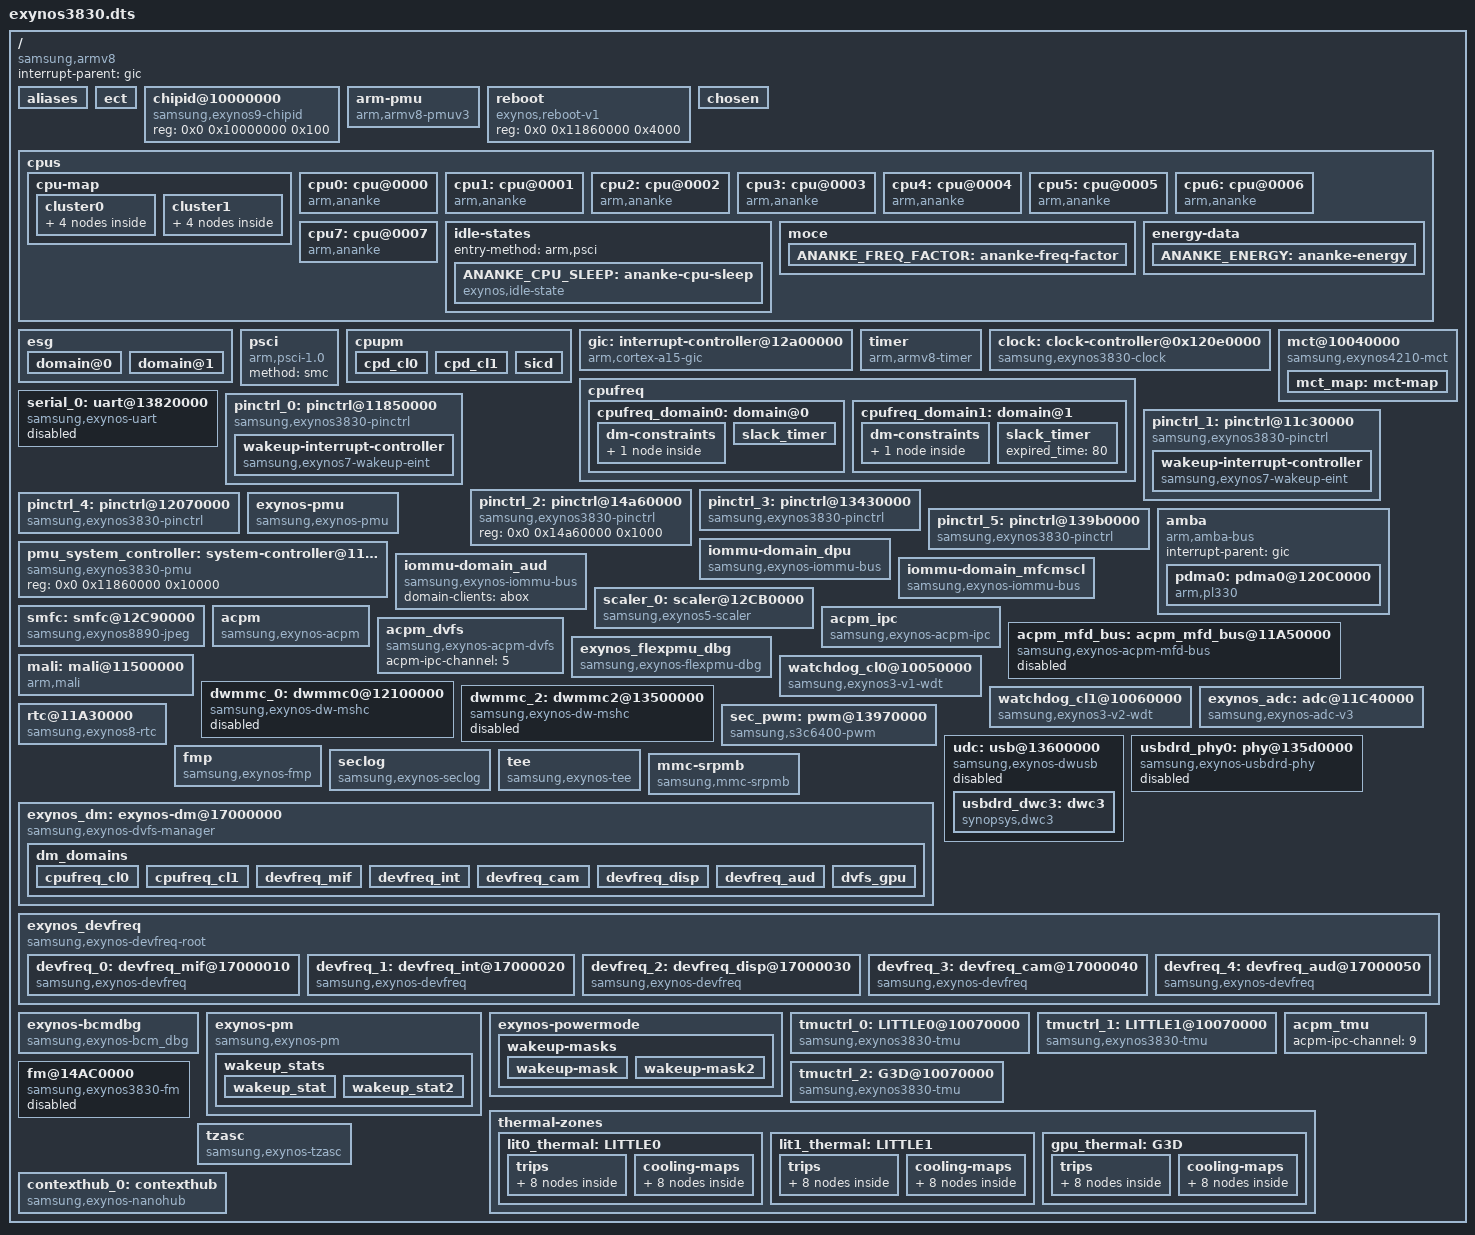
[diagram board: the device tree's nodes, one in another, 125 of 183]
/*
 * SAMSUNG EXYNOS3830 SoC device tree source
 *
 * Copyright (c) 2018 Samsung Electronics Co., Ltd.
 *		http://www.samsung.com
 *
 * SAMSUNG EXYNOS3830 SoC device nodes are listed in this file.
 * EXYNOS based board files can include this file and provide
 * values for board specfic bindings.
 *
 * This program is free software; you can redistribute it and/or modify
 * it under the terms of the GNU General Public License version 2 as
 * published by the Free Software Foundation.
 */

/dts-v1/;
#include <dt-bindings/interrupt-controller/arm-gic.h>
#include <dt-bindings/interrupt-controller/exynos3830.h>
#include <dt-bindings/clock/exynos3830.h>
#include <dt-bindings/soc/samsung/exynos3830-dm.h>
#include <dt-bindings/soc/samsung/exynos3830-devfreq.h>
#include <dt-bindings/soc/samsung/exynos-bcm_dbg.h>
#include "exynos3830-pinctrl.dtsi"
#include "exynos3830-rmem.dtsi"
#include "exynos3830-sysmmu.dtsi"
#include "exynos3830-dpu.dtsi"
#include "exynos3830-usi.dtsi"
#include "exynos3830-debug.dtsi"
#include "exynos-dpm.dtsi"
#include "exynos3830-pm-domains.dtsi"
#include "exynos3830-bts.dtsi"
#include "exynos3830-mfc.dtsi"
#include "exynos3830-camera.dtsi"
#include <dt-bindings/soc/samsung/exynos-ecs.h>
#include "exynos3830-wlbt.dtsi"
#include "exynos3830-ems.dtsi"
#include "exynos3830-audio.dtsi"
#include "exynos_perf_ncmemcpy.dtsi"

/ {
	compatible = "samsung,armv8", "samsung,exynos3830";
	interrupt-parent = <&gic>;
	#address-cells = <2>;
	#size-cells = <1>;

	aliases {
		pinctrl0 = &pinctrl_0;
		pinctrl1 = &pinctrl_1;
		pinctrl2 = &pinctrl_2;
		pinctrl3 = &pinctrl_3;
		pinctrl4 = &pinctrl_4;
		pinctrl5 = &pinctrl_5;
		uart0 = &serial_0;
		mshc0 = &dwmmc_0;
		mshc2 = &dwmmc_2;
		mfc0 = &mfc_0;
		scaler0 = &scaler_0;
		contexthub0 = &contexthub_0;
	};

	ect {
		parameter_address = <0x90000000>;
		parameter_size = <0x4B000>;
	};

	chipid@10000000 {
		compatible = "samsung,exynos9-chipid";
		reg = <0x0 0x10000000 0x100>;
	};

	arm-pmu {
		compatible = "arm,armv8-pmuv3";
		interrupts =	<0 INTREQ__CPUCL0_PMUIRQ_0 IRQ_TYPE_LEVEL_HIGH>,
				<0 INTREQ__CPUCL0_PMUIRQ_1 IRQ_TYPE_LEVEL_HIGH>,
				<0 INTREQ__CPUCL0_PMUIRQ_2 IRQ_TYPE_LEVEL_HIGH>,
				<0 INTREQ__CPUCL0_PMUIRQ_3 IRQ_TYPE_LEVEL_HIGH>,
				<0 INTREQ__CPUCL1_PMUIRQ_0 IRQ_TYPE_LEVEL_HIGH>,
				<0 INTREQ__CPUCL1_PMUIRQ_1 IRQ_TYPE_LEVEL_HIGH>,
				<0 INTREQ__CPUCL1_PMUIRQ_2 IRQ_TYPE_LEVEL_HIGH>,
				<0 INTREQ__CPUCL1_PMUIRQ_3 IRQ_TYPE_LEVEL_HIGH>;
		interrupt-affinity =	<&cpu0>,
					<&cpu1>,
					<&cpu2>,
					<&cpu3>,
					<&cpu4>,
					<&cpu5>,
					<&cpu6>,
					<&cpu7>;
	};

	reboot {
		compatible = "exynos,reboot-v1";
		reg = <0x0 0x11860000 0x4000>;
	};

	chosen: chosen {
		bootargs = "console=ttySAC0,115200n8 clk_ignore_unused root=/dev/ram0 androidboot.boot_devices=12100000.dwmmc0 androidboot.dtbo_idx=0 androidboot.debug_level=0x4948 firmware_class.path=/vendor/firmware pmic_info=0x3 ccic_info=0x0 reserve-fimc=0xffffff90f9fe0000";
		linux,initrd-start = <0x84000000>;
		linux,initrd-end = <0x841FFFFF>;
	};

	cpus {
		#address-cells = <2>;
		#size-cells = <0>;

		cpu-map {
			cluster0 {
				core0 {
					cpu = <&cpu0>;
				};
				core1 {
					cpu = <&cpu1>;
				};
				core2 {
					cpu = <&cpu2>;
				};
				core3 {
					cpu = <&cpu3>;
				};
			};

			cluster1 {
				core0 {
					cpu = <&cpu4>;
				};
				core1 {
					cpu = <&cpu5>;
				};
				core2 {
					cpu = <&cpu6>;
				};
				core3 {
					cpu = <&cpu7>;
				};
			};
		};

		cpu0: cpu@0000 {
			device_type = "cpu";
			compatible = "arm,ananke", "arm,armv8";
			reg = <0x0 0x0000>;
			enable-method = "psci";
			sched-energy-data = <&ANANKE_ENERGY>;
			cpu-idle-states = <&ANANKE_CPU_SLEEP>;
			moce-factors = <&ANANKE_FREQ_FACTOR>;
		};
		cpu1: cpu@0001 {
			device_type = "cpu";
			compatible = "arm,ananke", "arm,armv8";
			reg = <0x0 0x0001>;
			enable-method = "psci";
			sched-energy-data = <&ANANKE_ENERGY>;
			cpu-idle-states = <&ANANKE_CPU_SLEEP>;
			moce-factors = <&ANANKE_FREQ_FACTOR>;
		};
		cpu2: cpu@0002 {
			device_type = "cpu";
			compatible = "arm,ananke", "arm,armv8";
			reg = <0x0 0x0002>;
			enable-method = "psci";
			sched-energy-data = <&ANANKE_ENERGY>;
			cpu-idle-states = <&ANANKE_CPU_SLEEP>;
			moce-factors = <&ANANKE_FREQ_FACTOR>;
		};
		cpu3: cpu@0003 {
			device_type = "cpu";
			compatible = "arm,ananke", "arm,armv8";
			reg = <0x0 0x0003>;
			enable-method = "psci";
			sched-energy-data = <&ANANKE_ENERGY>;
			cpu-idle-states = <&ANANKE_CPU_SLEEP>;
			moce-factors = <&ANANKE_FREQ_FACTOR>;
		};
		cpu4: cpu@0004 {
			device_type = "cpu";
			compatible = "arm,ananke", "arm,armv8";
			reg = <0x0 0x0100>;
			enable-method = "psci";
			sched-energy-data = <&ANANKE_ENERGY>;
			cpu-idle-states = <&ANANKE_CPU_SLEEP>;
			moce-factors = <&ANANKE_FREQ_FACTOR>;
		};
		cpu5: cpu@0005 {
			device_type = "cpu";
			compatible = "arm,ananke", "arm,armv8";
			reg = <0x0 0x0101>;
			enable-method = "psci";
			sched-energy-data = <&ANANKE_ENERGY>;
			cpu-idle-states = <&ANANKE_CPU_SLEEP>;
			moce-factors = <&ANANKE_FREQ_FACTOR>;
		};
		cpu6: cpu@0006 {
			device_type = "cpu";
			compatible = "arm,ananke", "arm,armv8";
			reg = <0x0 0x0102>;
			enable-method = "psci";
			sched-energy-data = <&ANANKE_ENERGY>;
			cpu-idle-states = <&ANANKE_CPU_SLEEP>;
			moce-factors = <&ANANKE_FREQ_FACTOR>;
		};
		cpu7: cpu@0007 {
			device_type = "cpu";
			compatible = "arm,ananke", "arm,armv8";
			reg = <0x0 0x0103>;
			enable-method = "psci";
			sched-energy-data = <&ANANKE_ENERGY>;
			cpu-idle-states = <&ANANKE_CPU_SLEEP>;
			moce-factors = <&ANANKE_FREQ_FACTOR>;
		};

		idle-states {
			entry-method = "arm,psci";

			ANANKE_CPU_SLEEP: ananke-cpu-sleep {
				idle-state-name = "c2";
				compatible = "exynos,idle-state";
				arm,psci-suspend-param = <0x0010000>;
				entry-latency-us = <70>;
				exit-latency-us = <160>;
				min-residency-us = <2000>;
				status = "okay";
			};
		};

		moce {
			#define FREQ_FACTOR     0

			/* factor table format: [ratio][factor][ratio]...[ratio] */
			ANANKE_FREQ_FACTOR: ananke-freq-factor {
				sibling-cpus = "0-7";
				type = <FREQ_FACTOR>;
				ratio-table = <100>;
			};
		};

		energy-data {
			ANANKE_ENERGY: ananke-energy {
				mips-per-mhz = <271>;
				power-coefficient = <125>;
				mips-per-mhz-s = <215>;
				power-coefficient-s = <110>;
				static-power-coefficient = <10>;

				efficiency-weight = <100>;
				efficiency-weight-perf = <200>;
			};
		};
	};

	esg {
		domain@0 {
			device_type = "esgov-pol0";
			shared-cpus = "0-3";
			pm_qos-min-class = <3>;
			pm_qos-max-class = <4>;
			step = <4>;
		};
		domain@1 {
			device_type = "esgov-pol4";
			shared-cpus = "4-7";
			pm_qos-min-class = <5>;
			pm_qos-max-class = <6>;
			step = <4>;
		};
	};

	psci {
		compatible = "arm,psci-1.0";
		method = "smc";
	};

	cpupm {
		#define POWERMODE_TYPE_CLUSTER  0
		#define POWERMODE_TYPE_SYSTEM   1

		cpd_cl0 {
			device_type = "cpupm";
			target-residency = <10000>;
			psci-index = <128>;
			type = <POWERMODE_TYPE_CLUSTER>;
			siblings = "0-3";
		};

		cpd_cl1 {
			device_type = "cpupm";
			target-residency = <10000>;
			psci-index = <128>;
			type = <POWERMODE_TYPE_CLUSTER>;
			siblings = "4-7";
		};

               sicd {
                       device_type = "cpupm";
                       target-residency = <10000>;
                       psci-index = <256>;
                       type = <POWERMODE_TYPE_SYSTEM>;
                       siblings = "0-7";
		       entry-allowed = "0-7";
                       system-idle;
               };
	};

	gic:interrupt-controller@12a00000 {
		compatible = "arm,cortex-a15-gic", "arm,cortex-a9-gic";
		#interrupt-cells = <3>;
		#address-cells = <0>;
		interrupt-controller;
		reg =	<0x0 0x12a01000 0x1000>,
			<0x0 0x12a02000 0x1000>,
			<0x0 0x12a04000 0x2000>,
			<0x0 0x12a06000 0x2000>;
		interrupts = <1 9 0xf04>;
	};

	timer {
	        compatible = "arm,armv8-timer";
		interrupts = <GIC_PPI 13
				(GIC_CPU_MASK_SIMPLE(8) | IRQ_TYPE_LEVEL_LOW)>,
			     <GIC_PPI 14
				(GIC_CPU_MASK_SIMPLE(8) | IRQ_TYPE_LEVEL_LOW)>,
			     <GIC_PPI 11
				(GIC_CPU_MASK_SIMPLE(8) | IRQ_TYPE_LEVEL_LOW)>,
			     <GIC_PPI 10
				(GIC_CPU_MASK_SIMPLE(8) | IRQ_TYPE_LEVEL_LOW)>;
	        clock-frequency = <26000000>;
		use-clocksource-only;
		use-physical-timer;
	};

	clock: clock-controller@0x120e0000 {
		compatible = "samsung,exynos3830-clock";
		reg = <0x0 0x120e0000 0x8000>;
		#clock-cells = <1>;
		acpm-ipc-channel = <0>;
	};

	cpufreq {
		cpufreq_domain0: domain@0 {
			device_type = "cpufreq-domain";
			sibling-cpus = "0-3";
			cal-id = <ACPM_DVFS_CPUCL0>;
			dm-type = <DM_CPU_CL0>;

			min-freq = <546000>;

			/* PM QoS Class ID*/
			pm_qos-min-class = <3>;
			pm_qos-max-class = <4>;

			#cooling-cells = <2>; /* min followed by max */

			dm-constraints {
				mif-perf {
					const-type = <CONSTRAINT_MIN>;
					dm-type = <DM_MIF>;
					/*  cpu     mif  */
					table = < 2002000  1539000
						  1846000  1539000
						  1742000  1352000
						  1586000  1352000
						  1456000  1014000
						  1300000  1014000
						  1157000   845000
						  1053000   845000
						   949000   676000
						   806000   676000
						   650000   676000
						   546000   676000
						   442000   676000
						>;
				};
			};

			slack_timer {
				device_type = "slack-timer-domain";
			};
		};

		cpufreq_domain1: domain@1 {
			device_type = "cpufreq-domain";
			sibling-cpus = "4-7";
			cal-id = <ACPM_DVFS_CPUCL1>;
			dm-type = <DM_CPU_CL1>;

			min-freq = <546000>;

			/* PM QoS Class ID*/
			pm_qos-min-class = <5>;
			pm_qos-max-class = <6>;

			#cooling-cells = <2>; /* min followed by max */

			dm-constraints {
				mif-perf {
					const-type = <CONSTRAINT_MIN>;
					dm-type = <DM_MIF>;
					/*  cpu     mif  */
					table = < 2002000  1539000
						  1846000  1539000
						  1742000  1352000
						  1586000  1352000
						  1456000  1014000
						  1300000  1014000
						  1157000   845000
						  1053000   845000
						   949000   676000
						   806000   676000
						   650000   676000
						   546000   676000
						   442000   676000
						>;
				};
			};

			slack_timer {
				device_type = "slack-timer-domain";
				expired_time = <80>;	/* 80ms */
			};
		};
	};

	mct@10040000 {
		compatible = "samsung,exynos4210-mct";
		reg = <0x0 0x10040000 0x800>;
		interrupt-controller;
		#interrupt-cells = <1>;
		interrupt-parent = <&mct_map>;
		interrupts =	<0>, <1>, <2>, <3>,
				<4>, <5>, <6>, <7>,
				<8>, <9>, <10>, <11>;
		clocks = <&clock OSCCLK>, <&clock GATE_MCT_QCH>;
		clock-names = "fin_pll", "mct";
		use-clockevent-only;

		mct_map: mct-map {
			#interrupt-cells = <1>;
			#address-cells = <0>;
			#size-cells = <0>;
			interrupt-map = <0 &gic 0 INTREQ__MCT_G0 IRQ_TYPE_LEVEL_HIGH>,
					<1 &gic 0 INTREQ__MCT_G1 IRQ_TYPE_LEVEL_HIGH>,
					<2 &gic 0 INTREQ__MCT_G2 IRQ_TYPE_LEVEL_HIGH>,
					<3 &gic 0 INTREQ__MCT_G3 IRQ_TYPE_LEVEL_HIGH>,
					<4 &gic 0 INTREQ__MCT_L0 IRQ_TYPE_LEVEL_HIGH>,
					<5 &gic 0 INTREQ__MCT_L1 IRQ_TYPE_LEVEL_HIGH>,
					<6 &gic 0 INTREQ__MCT_L2 IRQ_TYPE_LEVEL_HIGH>,
					<7 &gic 0 INTREQ__MCT_L3 IRQ_TYPE_LEVEL_HIGH>,
					<8 &gic 0 INTREQ__MCT_L4 IRQ_TYPE_LEVEL_HIGH>,
					<9 &gic 0 INTREQ__MCT_L5 IRQ_TYPE_LEVEL_HIGH>,
					<10 &gic 0 INTREQ__MCT_L6 IRQ_TYPE_LEVEL_HIGH>,
					<11 &gic 0 INTREQ__MCT_L7 IRQ_TYPE_LEVEL_HIGH>;
		};
	};

	serial_0: uart@13820000 {
		compatible = "samsung,exynos-uart";
		samsung,separate-uart-clk;
		reg = <0x0 0x13820000 0x100>;
		samsung,fifo-size = <64>;
		interrupts = <0 INTREQ__UART 0>;
		pinctrl-names = "default","sleep";
		pinctrl-0 = <&uart0_bus>;
		pinctrl-1 = <&uart0_bus_sleep>;
		samsung,usi-serial-v2;
		samsung,dbg-uart-ch;
		samsung,dbg-uart-baud = <115200>;
		samsung,dbg-word-len = <8>;
		clocks = <&clock GATE_UART_QCH>, <&clock DOUT_UART>;
		clock-names = "gate_uart_clk0", "ipclk_uart0";
		status = "disabled";
	};

	/* ALIVE */
	pinctrl_0: pinctrl@11850000 {
		compatible = "samsung,exynos3830-pinctrl";
		reg = <0x0 0x11850000 0x1000>;
		interrupts = <GIC_SPI INTREQ__ALIVE_EINT0 IRQ_TYPE_LEVEL_HIGH>,
			     <GIC_SPI INTREQ__ALIVE_EINT1 IRQ_TYPE_LEVEL_HIGH>,
			     <GIC_SPI INTREQ__ALIVE_EINT2 IRQ_TYPE_LEVEL_HIGH>,
			     <GIC_SPI INTREQ__ALIVE_EINT3 IRQ_TYPE_LEVEL_HIGH>,
			     <GIC_SPI INTREQ__ALIVE_EINT4 IRQ_TYPE_LEVEL_HIGH>,
			     <GIC_SPI INTREQ__ALIVE_EINT5 IRQ_TYPE_LEVEL_HIGH>,
			     <GIC_SPI INTREQ__ALIVE_EINT6 IRQ_TYPE_LEVEL_HIGH>,
			     <GIC_SPI INTREQ__ALIVE_EINT7 IRQ_TYPE_LEVEL_HIGH>,
			     <GIC_SPI INTREQ__ALIVE_EINT8 IRQ_TYPE_LEVEL_HIGH>,
			     <GIC_SPI INTREQ__ALIVE_EINT9 IRQ_TYPE_LEVEL_HIGH>,
			     <GIC_SPI INTREQ__ALIVE_EINT10 IRQ_TYPE_LEVEL_HIGH>,
			     <GIC_SPI INTREQ__ALIVE_EINT11 IRQ_TYPE_LEVEL_HIGH>,
			     <GIC_SPI INTREQ__ALIVE_EINT12 IRQ_TYPE_LEVEL_HIGH>,
			     <GIC_SPI INTREQ__ALIVE_EINT13 IRQ_TYPE_LEVEL_HIGH>,
			     <GIC_SPI INTREQ__ALIVE_EINT14 IRQ_TYPE_LEVEL_HIGH>,
			     <GIC_SPI INTREQ__ALIVE_EINT15 IRQ_TYPE_LEVEL_HIGH>,
			     <GIC_SPI INTREQ__ALIVE_EINT16 IRQ_TYPE_LEVEL_HIGH>,
			     <GIC_SPI INTREQ__ALIVE_EINT17 IRQ_TYPE_LEVEL_HIGH>,
			     <GIC_SPI INTREQ__ALIVE_EINT18 IRQ_TYPE_LEVEL_HIGH>,
			     <GIC_SPI INTREQ__ALIVE_EINT19 IRQ_TYPE_LEVEL_HIGH>,
			     <GIC_SPI INTREQ__ALIVE_EINT20 IRQ_TYPE_LEVEL_HIGH>,
			     <GIC_SPI INTREQ__ALIVE_EINT21 IRQ_TYPE_LEVEL_HIGH>,
			     <GIC_SPI INTREQ__ALIVE_EINT22 IRQ_TYPE_LEVEL_HIGH>,
			     <GIC_SPI INTREQ__ALIVE_EINT23 IRQ_TYPE_LEVEL_HIGH>,
			     <GIC_SPI INTREQ__ALIVE_EINT24 IRQ_TYPE_LEVEL_HIGH>,
			     <GIC_SPI INTREQ__ALIVE_EINT25 IRQ_TYPE_LEVEL_HIGH>,
			     <GIC_SPI INTREQ__ALIVE_EINT26 IRQ_TYPE_LEVEL_HIGH>,
			     <GIC_SPI INTREQ__ALIVE_EINT27 IRQ_TYPE_LEVEL_HIGH>,
			     <GIC_SPI INTREQ__ALIVE_EINT28 IRQ_TYPE_LEVEL_HIGH>,
			     <GIC_SPI INTREQ__ALIVE_EINT29 IRQ_TYPE_LEVEL_HIGH>,
			     <GIC_SPI INTREQ__ALIVE_EINT30 IRQ_TYPE_LEVEL_HIGH>,
			     <GIC_SPI INTREQ__ALIVE_EINT31 IRQ_TYPE_LEVEL_HIGH>;

		wakeup-interrupt-controller {
			compatible = "samsung,exynos7-wakeup-eint";
		};
	};

	/* CMGP */
	pinctrl_1: pinctrl@11c30000 {
		compatible = "samsung,exynos3830-pinctrl";
		reg = <0x0 0x11c30000 0x1000>;
		interrupts = <GIC_SPI INTREQ__CMGP_EXT_INTM00 IRQ_TYPE_LEVEL_HIGH>,
			     <GIC_SPI INTREQ__CMGP_EXT_INTM01 IRQ_TYPE_LEVEL_HIGH>,
			     <GIC_SPI INTREQ__CMGP_EXT_INTM02 IRQ_TYPE_LEVEL_HIGH>,
			     <GIC_SPI INTREQ__CMGP_EXT_INTM03 IRQ_TYPE_LEVEL_HIGH>,
			     <GIC_SPI INTREQ__CMGP_EXT_INTM04 IRQ_TYPE_LEVEL_HIGH>,
			     <GIC_SPI INTREQ__CMGP_EXT_INTM05 IRQ_TYPE_LEVEL_HIGH>,
			     <GIC_SPI INTREQ__CMGP_EXT_INTM06 IRQ_TYPE_LEVEL_HIGH>,
			     <GIC_SPI INTREQ__CMGP_EXT_INTM07 IRQ_TYPE_LEVEL_HIGH>;

		wakeup-interrupt-controller {
			compatible = "samsung,exynos7-wakeup-eint";
		};
	};

	/* AUD */
	pinctrl_2: pinctrl@14a60000 {
		compatible = "samsung,exynos3830-pinctrl";
		reg = <0x0 0x14a60000 0x1000>;
	};

	/* HSI */
	pinctrl_3: pinctrl@13430000 {
		compatible = "samsung,exynos3830-pinctrl";
		reg = <0x0 0x13430000 0x1000>;
		interrupts = <GIC_SPI INTREQ__GPIO_HSI IRQ_TYPE_LEVEL_HIGH>;
	};

	/* CORE */
	pinctrl_4: pinctrl@12070000 {
		compatible = "samsung,exynos3830-pinctrl";
		reg = <0x0 0x12070000 0x1000>;
		interrupts = <GIC_SPI INTREQ__GPIO_CORE IRQ_TYPE_LEVEL_HIGH>;
	};

	/* PERI */
	pinctrl_5: pinctrl@139b0000 {
		compatible = "samsung,exynos3830-pinctrl";
		reg = <0x0 0x139b0000 0x1000>;
		interrupts = <GIC_SPI INTREQ__GPIO_PERI IRQ_TYPE_LEVEL_HIGH>;
	};

	exynos-pmu {
		compatible = "samsung,exynos-pmu";
		samsung,syscon-phandle = <&pmu_system_controller>;
		reg = <0x0 0x11860000 0x10000>;
		reg-names = "pmu_alive";
	};

	pmu_system_controller: system-controller@11860000 {
		compatible = "samsung,exynos3830-pmu", "syscon";
		reg = <0x0 0x11860000 0x10000>;
	};

	/* DMA */
	amba {
		#address-cells = <2>;
		#size-cells = <1>;
		compatible = "arm,amba-bus";
		interrupt-parent = <&gic>;
		ranges;

		pdma0: pdma0@120C0000 {
			compatible = "arm,pl330", "arm,primecell";
			reg = <0x0 0x120C0000 0x1000>;
			interrupts = <0 479 0>;
			clocks = <&clock GATE_PDMA_CORE_QCH>;
			clock-names = "apb_pclk";
			#dma-cells = <1>;
			#dma-channels = <8>;
			#dma-requests = <32>;
			#dma-multi-irq = <1>;
			dma-arwrapper = <0x120C4400>,
					<0x120C4420>,
					<0x120C4440>,
					<0x120C4460>,
					<0x120C4480>,
					<0x120C44A0>,
					<0x120C44C0>,
					<0x120C44E0>;
			dma-awwrapper = <0x120C4404>,
					<0x120C4424>,
					<0x120C4444>,
					<0x120C4464>,
					<0x120C4484>,
					<0x120C44A4>,
					<0x120C44C4>,
					<0x120C44E4>;
			dma-instwrapper = <0x120C4500>;
			dma-mask-bit = <36>;
			coherent-mask-bit = <36>;
		};
	};

	iommu-domain_dpu {
		compatible = "samsung,exynos-iommu-bus";
		#dma-address-cells = <1>;
		#dma-size-cells = <1>;
		ranges;
		/* start address, size */
		dma-window = <0x10000000 0xEFFF0000>;

		domain-clients = <&dsim_0>;
	};

	iommu-domain_aud {
		compatible = "samsung,exynos-iommu-bus";
		#address-cells = <2>;
		#size-cells = <1>;
		ranges;

		domain-clients = <&abox>;
	};

	iommu-domain_mfcmscl {
		compatible = "samsung,exynos-iommu-bus";
		#address-cells = <2>;
		#size-cells = <1>;
		ranges;

		domain-clients = <&mfc_0>, <&scaler_0>, <&smfc>,
					<&exynos_is>, <&is_sensor0>, <&is_sensor1>,
					<&is_sensor2>, <&camerapp_gdc>;
	};

	scaler_0: scaler@12CB0000 {
		compatible = "samsung,exynos5-scaler";
		reg = <0x0 0x12CB0000 0x3000>;
		interrupts = <0 170 0>;
		clocks = <&clock GATE_M2M_QCH>;
		clock-names = "gate";
		iommus = <&sysmmu_mfcmscl>;

		/* MIF | INT | datasize (not used) */
		mscl_qos_table = < 1352000 534000 0
				   1014000 334000 0
				    676000 200000 0
				    421000 100000 0 >;
		/* bpp means, YUV420(12), YUV422(16), RGB(32) */
		/* bpp | ppc * 100 | ppc * 100 with rotation */
		mscl_ppc_table = <  12  79 79
				    16  66 66
				    32  82 79 >;
	};

	smfc: smfc@12C90000 {
		compatible = "samsung,exynos8890-jpeg";
		reg = <0x0 0x12C90000 0x1000>;
		interrupts = <0 INTREQ__JPEG 0>;
		clocks = <&clock GATE_JPEG_QCH>;
		clock-names = "gate";
		iommus = <&sysmmu_mfcmscl>;
		smfc,int_qos_minlock = <534000>;
	};

	acpm {
		compatible = "samsung,exynos-acpm";
		#address-cells = <2>;
		#size-cells = <1>;
		acpm-ipc-channel = <4>;
		fvmap_offset = <0xA000>;
		reg = <0x0 0x11830000 0x1000>;		/* TIMER_APM */
		reg-names = "timer_apm";
		peritimer-cnt = <0xFFFF>;
	};

	acpm_ipc {
		compatible = "samsung,exynos-acpm-ipc";
		#address-cells = <2>;
		#size-cells = <1>;
		interrupts = <0 INTREQ__MAILBOX_APM2AP 0>;	/* AP2APM MAILBOX SPI NUM*/
		reg = <0x0 0x11900000 0x1000>,		/* AP2APM MAILBOX */
			<0x0 0x2039000 0x30000>;	/* APM SRAM */
		initdata-base = <0x7000>;
		num-timestamps = <32>;
		debug-log-level = <0>;
		logging-period = <500>;
		dump-base = <0x203C000>;
		dump-size = <0x2D000>;			/* 180KB */
	};

	acpm_dvfs {
		compatible = "samsung,exynos-acpm-dvfs";
		acpm-ipc-channel = <5>;
	};

	acpm_mfd_bus: acpm_mfd_bus@11A50000 {
		compatible = "samsung,exynos-acpm-mfd-bus";
		status = "disabled";
	};

	exynos_flexpmu_dbg {
		compatible = "samsung,exynos-flexpmu-dbg";
		#address-cells = <2>;
		#size-cells = <1>;
		data-base = <0x204D400>;
		data-size = <0x400>;
		reg = <0x0 0x11a30000 0x1000>;
	};

    /* mali */
    mali: mali@11500000 {
        compatible = "arm,mali";
        reg = <0x0 0x11500000 0x5000>;
        interrupts = <GIC_SPI INTREQ__G3D_IRQJOB IRQ_TYPE_LEVEL_HIGH>,
                   <GIC_SPI INTREQ__G3D_IRQMMU IRQ_TYPE_LEVEL_HIGH>,
                   <GIC_SPI INTREQ__G3D_IRQGPU IRQ_TYPE_LEVEL_HIGH>;
        interrupt-names = "JOB", "MMU", "GPU";
        g3d_cmu_cal_id = <ACPM_DVFS_G3D>;
        samsung,power-domain = <&pd_g3d>;
        g3d_genpd_name = "pd-g3d";
        #cooling-cells = <2>; /* min followed by max */
        governor = "interactive";
        interactive_info = <377000 75 0>;
        gpu_dvfs_table_size = <6 7>; /*<row col>*/
        /*  8 columns          freq  down   up stay     mif  little     big  */
        gpu_dvfs_table = <  1001000    95  100   1  1539000 2002000       0
                             865000    80   90   1  1539000 2002000       0
                             754000    80   90   1  1352000 1456000       0
                             598000    70   90   1  1014000 1053000       0
                             433000    60   80   1   845000  806000       0
                             377000     0   70   1   676000  650000       0  >;
        gpu_sustainable_info = <0 0 0 0 0>;
        gpu_pmqos_cpu_cluster_num = <2>;
        gpu_pmu_status_reg_offset = <0x1d04>;
        gpu_pmu_status_local_pwr_mask = <0x1>; /*0x1 << 0*/
        gpu_max_clock = <1001000>;
        gpu_max_clock_limit = <1001000>;
        gpu_min_clock = <377000>;
        gpu_dvfs_start_clock = <377000>;
        gpu_dvfs_bl_config_clock = <377000>;
        gpu_default_voltage = <800000>;
        gpu_cold_minimum_vol = <0>;
        gpu_voltage_offset_margin = <37500>;
        gpu_tmu_control = <1>;
        gpu_temp_throttling_level_num = <6>;
        gpu_temp_throttling = <598000 433000 377000 156000 100000 100000>;
        gpu_power_coeff = <625>;
        gpu_dvfs_time_interval = <5>; /*1 tick : 10ms*/
        gpu_default_wakeup_lock = <1>;
        gpu_dynamic_abb = <0>;
        gpu_early_clk_gating = <0>;
        gpu_dvs = <0>;
        gpu_inter_frame_pm = <0>;
        gpu_perf_gathering = <0>;
        gpu_runtime_pm_delay_time = <50>;
        gpu_dvfs_polling_time = <30>;
        gpu_pmqos_int_disable = <1>;
        gpu_pmqos_mif_max_clock = <2094000>;
        gpu_pmqos_mif_max_clock_base = <650000>;
        gpu_cl_dvfs_start_base = <377000>;
        gpu_debug_level = <3>; /*DEBUG(1) INFO(2) WARNING(3) ERROR(4)*/
        gpu_trace_level = <8>; /*TRACE_ALL*/
        gpu_mo_min_clock = <377000>;
        gpu_boost_gpu_min_lock = <0>;
        gpu_boost_egl_min_lock = <1872000>;
        gpu_vk_boost_max_lock = <325000>;
        gpu_vk_boost_mif_min_lock = <1014000>;
        gpu_bts_support = <1>;
    };

	dwmmc_0: dwmmc0@12100000 {
		compatible = "samsung,exynos-dw-mshc";
		reg = <0x0 0x12100000 0x2000>,
		    <0x0 0x12108000 0x200>;
		reg-names = "dw_mmc",
			"cmdq_mem";
		interrupts = <0 INTREQ__MMC_EMBD_CORE 0>;
		#address-cells = <1>;
		#size-cells = <0>;
		clocks = <&clock DOUT_CORE_MMC_EMBD>;
		clock-names = "ciu";
		status = "disabled";
		fmp-id = <0>;
		smu-id = <0>;
	 };

	dwmmc_2: dwmmc2@13500000 {
		compatible = "samsung,exynos-dw-mshc";
		reg = <0x0 0x13500000 0x2000>;
		reg-names = "dw_mmc";
		interrupts = <0 INTREQ__MMC_CARD 0>;
		#address-cells = <1>;
		#size-cells = <0>;
		clocks = <&clock HSI_MMC_CARD>;
		clock-names = "ciu";
		samsung,power-domain = <&pd_hsi>;
		status = "disabled";
	 };

	watchdog_cl0@10050000 {
		compatible = "samsung,exynos3-v1-wdt";
		reg = <0x0 0x10050000 0x100>;
		interrupts = <GIC_SPI INTREQ__WDT_0 IRQ_TYPE_LEVEL_HIGH>;
		clocks = <&clock OSCCLK>, <&clock GATE_WDT_0_QCH>;
		clock-names = "rate_watchdog", "gate_watchdog";
		timeout-sec = <30>;
		samsung,syscon-phandle = <&pmu_system_controller>;
		index = <0>; /* if little cluster then index is 0*/
	};

	watchdog_cl1@10060000 {
		compatible = "samsung,exynos3-v2-wdt";
		reg = <0x0 0x10060000 0x100>;
		interrupts = <GIC_SPI INTREQ__WDT_1 IRQ_TYPE_LEVEL_HIGH>;
		clocks = <&clock OSCCLK>, <&clock GATE_WDT_1_QCH>;
		clock-names = "rate_watchdog", "gate_watchdog";
		timeout-sec = <30>;
		samsung,syscon-phandle = <&pmu_system_controller>;
		index = <1>; /* if little cluster then index is 0*/
		use_multistage_wdt; /* Use FIQ debug watchdog */
	};

	exynos_adc: adc@11C40000 {
		compatible = "samsung,exynos-adc-v3";
		reg = <0x0 0x11C40000 0x100>;
		interrupts = <GIC_SPI INTREQ__ADC_CMGP2AP IRQ_TYPE_LEVEL_HIGH>;
		#io-channel-cells = <1>;
		io-channel-ranges;
		clocks = <&clock GATE_ADC_CMGP_QCH_S0>;
		clock-names = "gate_adcif";
	};

	sec_pwm: pwm@13970000 {
		compatible = "samsung,s3c6400-pwm";
		reg = <0x0 0x13970000 0x1000>;
		samsung,pwm-outputs = <0>, <1>, <2>, <3>, <4>;
		#pwm-cells = <3>;
		clocks = <&clock GATE_PWM_MOTOR_QCH>, <&clock OSCCLK>;
		clock-names = "pwm_pclk", "pwm_sclk";
		pinctrl-names = "default";
#if 0 //dw.choi
		pinctrl-0 = <&motor_pwm_tout0>;
#endif
		status = "ok";
	};

	rtc@11A30000 {
		compatible = "samsung,exynos8-rtc";
		reg = <0x0 0x11A30000 0x100>;
		interrupts = <GIC_SPI INTREQ__RTC_ALARM_INT IRQ_TYPE_LEVEL_HIGH>,
			     <GIC_SPI INTREQ__RTC_TIC_INT_0 IRQ_TYPE_LEVEL_HIGH>;
	};

	udc: usb@13600000 {
		compatible = "samsung,exynos-dwusb";
		pinctrl-names = "default";
		pinctrl-0 = <&fm_lna_en>;
		clocks = <&clock GATE_USB20DRD_TOP_QCH_LINK>, <&clock HSI_USB20DRD>;
		clock-names = "aclk", "sclk";
		reg = <0x0 0x13600000 0x10000>;
		#address-cells = <2>;
		#size-cells = <1>;
		ranges;
		samsung,power-domain = <&pd_hsi>;
		status = "disabled";

		usbdrd_dwc3: dwc3 {
			compatible = "synopsys,dwc3";
			reg = <0x0 0x13600000 0x10000>;
			interrupts = <0 INTREQ__USB20DRD_0 0>;
			tx-fifo-resize = <0>;
			adj-sof-accuracy = <0>;
			is_not_vbus_pad = <1>;
			enable_sprs_transfer = <1>;
			phys = <&usbdrd_phy0 0>, <&usbdrd_phy0 1>;
			phy-names = "usb2-phy", "usb3-phy";
			/* check susphy support */
			xhci_l2_support = <0>;
			/* support usb audio offloading: 1, if not: 0 */
			usb_audio_offloading = <0>;
			//abox = <&abox>; /* Temporary block */
			/* support USB L2 sleep */
			ldos = <3>;
			ldo_number = <1 2 11>;
		};
	};

	usbdrd_phy0: phy@135d0000 {
		compatible = "samsung,exynos-usbdrd-phy";
		reg = <0x0 0x135d0000 0x200>;
		interrupts = <0 INTREQ__USB2_REMOTE_WAKEUP 0>,
			     <0 INTREQ__USB2_REMOTE_CONNECT 0>;
		clocks = <&clock OSCCLK>, <&clock GATE_USB20DRD_TOP_QCH_LINK>;
		clock-names = "ext_xtal", "aclk";
		samsung,pmu-syscon = <&pmu_system_controller>;
		pmu_mask = <0x0>;
		pmu_offset = <0x704>;
		pmu_offset_dp = <0x704>;

		/* USBDP combo phy version  - 0x200 */
		phy_version = <0x301>;
		/* if it doesn't need phy user mux, */
		/*  you should write "none" */
		/*  but refclk shouldn't be omitted */
		phyclk_mux = "none";
		phy_refclk = "ext_xtal";

		/* if Main phy has the other phy, it must be set to 1. jusf for usbphy_info */
		has_other_phy = <0>;
		/* if combo phy is used, it must be set to 1. usbphy_sub_info is enabled */
		has_combo_phy = <0>;
		sub_phy_version = <0x400>;

		/* ip type */
		/* USB3DRD = 0 */
		/*  USB3HOST = 1 */
		/*  USB2DRD = 2 */
		/*  USB2HOST = 3 */
		ip_type = <0x0>;

		/* for PHY CAL */
		/* choice only one item */
		phy_refsel_clockcore = <1>;
		phy_refsel_ext_osc = <0>;
		phy_refsel_xtal = <0>;
		phy_refsel_diff_pad = <0>;
		phy_refsel_diff_internal = <0>;
		phy_refsel_diff_single = <0>;

		/* true : 1 , false : 0 */
		use_io_for_ovc = <0>;
		common_block_disable = <1>;
		is_not_vbus_pad = <1>;
		used_phy_port = <0>;

		status = "disabled";

		#phy-cells = <1>;
		ranges;
       };

	fmp: fmp {
		compatible = "samsung,exynos-fmp";
		exynos,block-type = "mmcblk0p";
		exynos,fips-block_offset = <5>;
	};

	/* Secure Log */
	seclog {
		compatible = "samsung,exynos-seclog";
		interrupts = <GIC_SPI INTREQ__SECURE_LOG IRQ_TYPE_LEVEL_HIGH>;
	};

	/* tbase */
	tee {
		compatible = "samsung,exynos-tee";
		interrupts = <GIC_SPI INTREQ__TBASE IRQ_TYPE_LEVEL_HIGH>;
	};

	/* Secure RPMB */
	mmc-srpmb {
		compatible = "samsung,mmc-srpmb";
		interrupts = <GIC_SPI INTREQ__RPMB IRQ_TYPE_LEVEL_HIGH>;
	};

	exynos_dm: exynos-dm@17000000 {
		compatible = "samsung,exynos-dvfs-manager";
		reg = <0x0 0x17000000 0x0>;
		acpm-ipc-channel = <1>;
		dm_domains {
			cpufreq_cl0 {
				dm-index = <DM_CPU_CL0>;
				available = "true";
				cal_id = <ACPM_DVFS_CPUCL0>;
				dm_type_name = "dm_cpu_cl0";
			};
			cpufreq_cl1 {
				dm-index = <DM_CPU_CL1>;
				available = "true";
				cal_id = <ACPM_DVFS_CPUCL1>;
				dm_type_name = "dm_cpu_cl1";
			};
			devfreq_mif {
				dm-index = <DM_MIF>;
				available = "true";
				policy_use = "true";
				cal_id = <ACPM_DVFS_MIF>;
				dm_type_name = "dm_mif";
			};
			devfreq_int {
				dm-index = <DM_INT>;
				available = "true";
				policy_use = "true";
				cal_id = <ACPM_DVFS_INT>;
				dm_type_name = "dm_int";
			};
			devfreq_cam {
				dm-index = <DM_CAM>;
				available = "true";
				cal_id = <ACPM_DVFS_CAM>;
				dm_type_name = "dm_cam";
			};
			devfreq_disp {
				dm-index = <DM_DISP>;
				available = "true";
				cal_id = <ACPM_DVFS_DISP>;
				dm_type_name = "dm_disp";
			};
			devfreq_aud {
				dm-index = <DM_AUD>;
				available = "true";
				cal_id = <ACPM_DVFS_AUD>;
				dm_type_name = "dm_aud";
			};
			dvfs_gpu {
				dm-index = <DM_GPU>;
				available = "false";
				cal_id = <ACPM_DVFS_G3D>;
				dm_type_name = "dm_gpu";
			};
		};
	};

	exynos_devfreq {
		compatible = "samsung,exynos-devfreq-root";
		#address-cells = <2>;
		#size-cells = <1>;
		ranges;
		devfreq_0: devfreq_mif@17000010 {
			compatible = "samsung,exynos-devfreq";
			reg = <0x0 0x17000010 0x0>;
			devfreq_type = <DEVFREQ_MIF>;
			devfreq_domain_name = "MIF";
			pm_qos_class = <DT_PM_QOS_BUS_THROUGHPUT>; /* PM_QOS_BUS_THROUGHPUT */
			pm_qos_class_max = <DT_PM_QOS_BUS_THROUGHPUT_MAX>; /* PM_QOS_BUS_THROUGHPUT_MAX */
			ess_flag = <ESS_FLAG_MIF>;
			dm-index = <DM_MIF>;

			/* Delay time */
			use_delay_time = "false";

			freq_info = <1539000 421000 421000 421000 1539000 421000>;
			/* initial_freq, default_qos, suspend_freq, min_freq, max_freq reboot_freq */

			/* Booting value */
			boot_info = <40 1539000>;
			/* boot_qos_timeout, boot_freq */

			/* governor data */
			governor = <SIMPLE_INTERACTIVE>;

			bts_update = "false";
			dfs_id = <ACPM_DVFS_MIF>;
			acpm-ipc-channel = <1>;
			use_acpm = "true";
			update_fvp = "true";
		};

		devfreq_1: devfreq_int@17000020 {
			compatible = "samsung,exynos-devfreq";
			reg = <0x0 0x17000020 0x0>;
			devfreq_type = <DEVFREQ_INT>;
			devfreq_domain_name = "INT";
			pm_qos_class = <DT_PM_QOS_DEVICE_THROUGHPUT>; /* PM_QOS_DEVICE_THROUGHPUT */
			pm_qos_class_max = <DT_PM_QOS_DEVICE_THROUGHPUT_MAX>; /* PM_QOS_DEVICE_THROUGHPUT_MAX */
			ess_flag = <ESS_FLAG_INT>;
			dm-index = <DM_INT>;

			/* Delay time */
			use_delay_time = "false";

			freq_info = <667000 50000 50000 50000 667000 667000>;
			/* <initial_freq, default_qos, suspend_freq, min, max, reboot_freq> */

			/* Booting value */
			boot_info = <40 667000>;
			/* boot_qos_timeout, boot_freq */

			/* governor data */
			governor = <SIMPLE_INTERACTIVE>;

			bts_update = "false";
			dfs_id = <ACPM_DVFS_INT>;
			acpm-ipc-channel = <1>;
			use_acpm = "true";
		};

		devfreq_2: devfreq_disp@17000030 {
			compatible = "samsung,exynos-devfreq";
			reg = <0x0 0x17000030 0x0>;
			devfreq_type = <DEVFREQ_DISP>;
			devfreq_domain_name = "DISP";
			pm_qos_class = <DT_PM_QOS_DISPLAY_THROUGHPUT>; /* PM_QOS_DISPLAY_THROUGHPUT */
			pm_qos_class_max = <DT_PM_QOS_DISPLAY_THROUGHPUT_MAX>; /* PM_QOS_DISPLAY_THROUGHPUT_MAX */
			ess_flag = <ESS_FLAG_DISP>;
			dm-index = <DM_DISP>;

			/* Delay time */
			use_delay_time = "false";

			freq_info = <400000 50000 50000 50000 400000 400000>;
			/* <initial_freq, default_qos, suspend_freq, min, max, reboot_freq> */

			/* Booting value */
			boot_info = <40 400000>;
			/* boot_qos_timeout, boot_freq */

			/* governor data */
			governor = <SIMPLE_INTERACTIVE>;

			bts_update = "false";
			dfs_id = <ACPM_DVFS_DISP>;
		};

		devfreq_3: devfreq_cam@17000040 {
			compatible = "samsung,exynos-devfreq";
			reg = <0x0 0x17000040 0x0>;
			devfreq_type = <DEVFREQ_CAM>;
			devfreq_domain_name = "CAM";
			pm_qos_class = <DT_PM_QOS_CAM_THROUGHPUT>; /* PM_QOS_CAM_THROUGHPUT */
			pm_qos_class_max = <DT_PM_QOS_CAM_THROUGHPUT_MAX>; /* PM_QOS_CAM_THROUGHPUT_MAX */
			ess_flag = <ESS_FLAG_CAM>;
			dm-index = <DM_CAM>;

			/* Delay time */
			use_delay_time = "false";

			freq_info = <690000 650000 65000 650000 690000 650000>;
			/* <initial, default_qos, suspend_freq, min, max, reboot_freq> */

			/* Booting value */
			boot_info = <40 650000>;
			/* boot_qos_timeout, boot_freq */

			/* governor data */
			governor = <SIMPLE_INTERACTIVE>;

			bts_update = "false";

			dfs_id = <ACPM_DVFS_CAM>;
		};

		devfreq_4: devfreq_aud@17000050 {
			compatible = "samsung,exynos-devfreq";
			reg = <0x0 0x17000050 0x0>;
			devfreq_type = <DEVFREQ_AUD>;
			devfreq_domain_name = "AUD";
			pm_qos_class = <DT_PM_QOS_AUD_THROUGHPUT>; /* PM_QOS_AUD_THROUGHPUT */
			pm_qos_class_max = <DT_PM_QOS_AUD_THROUGHPUT_MAX>; /* PM_QOS_AUD_THROUGHPUT_MAX */
			ess_flag = <ESS_FLAG_AUD>;
			dm-index = <DM_AUD>;

			/* Delay time */
			use_delay_time = "false";

			freq_info = <1033000 259000 259000 259000 1033000 259000>;
			/* <initial, default_qos, suspend_freq, min, max, reboot_freq> */

			/* Booting value */
			boot_info = <40 259000>;
			/* boot_qos_timeout, boot_freq */

			/* governor data */
			governor = <SIMPLE_INTERACTIVE>;

			bts_update = "false";
			dfs_id = <ACPM_DVFS_AUD>;

			samsung,power-domain = <&pd_aud>;
			pd_name = "pd-aud";
		};
	};

	exynos-bcmdbg {
		compatible = "samsung,exynos-bcm_dbg";

		pd-name = "pd-trex", "pd-aud", "pd-dpu", "pd-mfcmscl", "pd-is",
			  "pd-hsi";

		max_define_event = <PRE_DEFINE_EVT_MAX>;
		bcm_cnt_nr = <8>;
		/* define_event_index ev0 ev1 ev2 ev3 ev4 ev5 ev6 ev7 */
		define_events = <NO_PRE_DEFINE_EVT	0x0  0x0  0x0  0x0  0x0  0x0  0x0  0x0>,
				<LATENCY_FMT_EVT	0x4  0x2  0x26 0x24 0x5  0x3  0x27 0x25>,
				<MO_FMT_EVT		0x4  0x0  0x24 0x24 0x5  0x1  0x25 0x25>,
				<BURST_LENGTH_FMT_EVT	0x4  0x2  0x4  0x26 0x5  0x3  0x5  0x27>,
				<REQ_BLOCK_FMT_EVT	0x2  0x10 0x10 0x26 0x3  0x11 0x11 0x27>,
				<DATA_BLOCK_FMT_EVT	0x4  0x12 0x12 0x6  0x5  0x13 0x13 0x14>,
				<REQ_TYPE_FMT_EVT	0x2  0x15 0x18 0x1B 0x3  0x16 0x19 0x1C>;
		default_define_event = <LATENCY_FMT_EVT>;

		/* sm_id_mask sm_id_value */
		define_filter_id = <NO_PRE_DEFINE_EVT	0x0  0x0>,
				<LATENCY_FMT_EVT	0x0  0x0>,
				<MO_FMT_EVT		0x0  0x0>,
				<BURST_LENGTH_FMT_EVT	0x0  0x0>,
				<REQ_BLOCK_FMT_EVT	0x0  0x0>,
				<DATA_BLOCK_FMT_EVT	0x0  0x0>,
				<REQ_TYPE_FMT_EVT	0x0  0x0>;
		/* ev0 ev1 ev2 ev3 ev4 ev5 ev6 ev7 */
		define_filter_id_active = <NO_PRE_DEFINE_EVT	0x0  0x0  0x0  0x0  0x0  0x0  0x0  0x0>,
					<LATENCY_FMT_EVT	0x0  0x0  0x0  0x0  0x0  0x0  0x0  0x0>,
					<MO_FMT_EVT		0x0  0x0  0x0  0x0  0x0  0x0  0x0  0x0>,
					<BURST_LENGTH_FMT_EVT	0x0  0x0  0x0  0x0  0x0  0x0  0x0  0x0>,
					<REQ_BLOCK_FMT_EVT	0x0  0x0  0x0  0x0  0x0  0x0  0x0  0x0>,
					<DATA_BLOCK_FMT_EVT	0x0  0x0  0x0  0x0  0x0  0x0  0x0  0x0>,
					<REQ_TYPE_FMT_EVT	0x0  0x0  0x0  0x0  0x0  0x0  0x0  0x0>;
		/* sm_other_type0 sm_other_mask0 sm_other_value0 */
		define_filter_other_0 = <NO_PRE_DEFINE_EVT	0x0  0x0  0x0>,
					<LATENCY_FMT_EVT	0x0  0x0  0x0>,
					<MO_FMT_EVT		0x0  0x0  0x0>,
					<BURST_LENGTH_FMT_EVT	0x0  0x0  0x0>,
					<REQ_BLOCK_FMT_EVT	0x0  0x0  0x0>,
					<DATA_BLOCK_FMT_EVT	0x0  0x0  0x0>,
					<REQ_TYPE_FMT_EVT	0x0  0x0  0x0>;
		/* sm_other_type1 sm_other_mask1 sm_other_value1 */
		define_filter_other_1 = <NO_PRE_DEFINE_EVT	0x0  0x0  0x0>,
					<LATENCY_FMT_EVT	0x0  0x0  0x0>,
					<MO_FMT_EVT		0x0  0x0  0x0>,
					<BURST_LENGTH_FMT_EVT	0x0  0x0  0x0>,
					<REQ_BLOCK_FMT_EVT	0x0  0x0  0x0>,
					<DATA_BLOCK_FMT_EVT	0x0  0x0  0x0>,
					<REQ_TYPE_FMT_EVT	0x0  0x0  0x0>;
		/* ev0 ev1 ev2 ev3 ev4 ev5 ev6 ev7 */
		define_filter_other_active = <NO_PRE_DEFINE_EVT	0x0  0x0  0x0  0x0  0x0  0x0  0x0  0x0>,
					<LATENCY_FMT_EVT	0x0  0x0  0x0  0x0  0x0  0x0  0x0  0x0>,
					<MO_FMT_EVT		0x0  0x0  0x0  0x0  0x0  0x0  0x0  0x0>,
					<BURST_LENGTH_FMT_EVT	0x0  0x0  0x0  0x0  0x0  0x0  0x0  0x0>,
					<REQ_BLOCK_FMT_EVT	0x0  0x0  0x0  0x0  0x0  0x0  0x0  0x0>,
					<DATA_BLOCK_FMT_EVT	0x0  0x0  0x0  0x0  0x0  0x0  0x0  0x0>,
					<REQ_TYPE_FMT_EVT	0x0  0x0  0x0  0x0  0x0  0x0  0x0  0x0>;

		/* peak_mask peak_id */
		define_sample_id = <NO_PRE_DEFINE_EVT	0x0  0x0>,
				<LATENCY_FMT_EVT	0x0  0x0>,
				<MO_FMT_EVT		0x0  0x0>,
				<BURST_LENGTH_FMT_EVT	0x0  0x0>,
				<REQ_BLOCK_FMT_EVT	0x0  0x0>,
				<DATA_BLOCK_FMT_EVT	0x0  0x0>,
				<REQ_TYPE_FMT_EVT	0x0  0x0>;
		/* ev0 ev1 ev2 ev3 ev4 ev5 ev6 ev7 */
		define_sample_id_enable = <NO_PRE_DEFINE_EVT	0x0  0x0  0x0  0x0  0x0  0x0  0x0  0x0>,
					<LATENCY_FMT_EVT	0x0  0x0  0x1  0x0  0x0  0x0  0x1  0x0>,
					<MO_FMT_EVT		0x0  0x0  0x1  0x0  0x0  0x0  0x1  0x0>,
					<BURST_LENGTH_FMT_EVT	0x0  0x0  0x1  0x1  0x0  0x0  0x1  0x1>,
					<REQ_BLOCK_FMT_EVT	0x0  0x0  0x1  0x1  0x0  0x0  0x1  0x1>,
					<DATA_BLOCK_FMT_EVT	0x0  0x0  0x1  0x0  0x0  0x0  0x1  0x0>,
					<REQ_TYPE_FMT_EVT	0x0  0x0  0x0  0x0  0x0  0x0  0x0  0x0>;

		bcm_ip_nr = <24>;
		bcm_ip_print_nr = <10>;
		initial_run_bcm_ip = <0>, <1>, <2>, <3>, <4>, <5>, <6>, <7>, <8>, <9>, <10>,
				<11>, <12>, <13>, <14>, <15>, <16>, <17>, <18>,	<19>, <20>,
				<21>, <22>, <23>;
		initial_bcm_run = <BCM_STOP>;
		/* msec (max 500msec) */
		initial_period = <1>;
		initial_bcm_mode = <BCM_MODE_INTERVAL>;
		available_stop_owner = <PANIC_HANDLE CAMERA_DRIVER MODEM_IF ITMON_HANDLE>;
		buff_size = <0x100000>;
		glb_auto_en = <1>;
	};

	exynos-pm {
		compatible = "samsung,exynos-pm";
		reg = <0x0 0x11850000 0x1000>,
		    <0x0 0x12a01200 0x100>;
		reg-names = "gpio_alive_base",
			"gicd_ispendrn_base";
		num-eint = <16>;
		num-gic = <16>;
		suspend_mode_idx = <8>;         /* SYS_SLEEP */
		suspend_psci_idx = <1024>;      /* PSCI_SYSTEM_SLEEP */

		usbl2_suspend_available = <0>;  /* SYS_SLEEP_USBL2 */
		usbl2_suspend_mode_idx = <12>;  /* PSCI_SYSTEM_SLEEP */

		/* WAKEUP_STAT,      WAKEUP2_STAT*/
		wakeup_stat = <0x3950>,         <0x3954>;

		wake_lock = <0>;		/* 1: held wake_lock */

		wakeup_stats {
			wakeup_stat {
				ws-name =
					"RTC_ALARM",		/* [ 0] */
					"RTC_TICK",		/* [ 1] */
					"TRTC_ALARM",		/* [ 2] */
					"TRTC_TICK",		/* [ 3] */
					"RESERVED",		/* [ 4] */
					"CMGP2PMU_AP_EINT0",	/* [ 5] */
					"CMGP2PMU_AP_EINT1",	/* [ 6] */
					"AUD_ABOX_GIC400",	/* [ 7] */
					"MAILBOX_CHUB2AP",	/* [ 8] */
					"MAILBOX_GNSS2AP",	/* [ 9] */
					"MAILBOX_WLBT2AP",	/* [10] */
					"MAILBOX_AP2AP",	/* [11] */
					"MAILBOX_CP2AP",	/* [12] */
					"S_MAILBOX_CP2AP",	/* [13] */
					"CHUB_WDT",		/* [14] */
					"EINT",			/* [15] */
					"USB_REWA",		/* [16] */
					"USB20",		/* [17] */
					"MMC_EMBD",		/* [18] */
					"MMC_CARD",		/* [19] */
					"TIMER",		/* [20] */
					"CP_RESET_REQ",		/* [21] */
					"GNSS_RESET_REQ",	/* [22] */
					"GNSS_ACTIVE",		/* [23] */
					"GNSS_WAKEUP_REQ",	/* [24] */
					"WLBT_RESET_REQ",	/* [25] */
					"WLBT_ACTIVE",		/* [26] */
					"CLUSTER0_CPU0_nIRQ",	/* [27] */
					"CLUSTER0_CPU1_nIRQ",	/* [28] */
					"CLUSTER0_CPU2_nIRQ",	/* [29] */
					"CLUSTER0_CPU3_nIRQ",	/* [30] */
					"RESERVED";		/* [31] */
			};
			wakeup_stat2 {
				ws-name =
					"USB20_PHY_FS_VMINUS",	/* [ 0] */
					"USB20_PHY_FS_VPLUS",	/* [ 1] */
					"CLUSTER1_CPU0_nIRQ",	/* [ 2] */
					"CLUSTER1_CPU1_nIRQ",	/* [ 3] */
					"CLUSTER1_CPU2_nIRQ",	/* [ 4] */
					"CLUSTER1_CPU3_nIRQ";	/* [ 5] */
			};
		};
	};

	exynos-powermode {
		wakeup-masks {
			/*
			 * wakeup_mask configuration
			 *	        SICD		SICD_CPD	AFTR		STOP
			 *              LPD		LPA		ALPA		DSTOP
			 *              SLEEP		SLEEP_VTS_ON	SLEEP_AUD_ON	FAPO
			 *		USB_L2		HSI2ON
			 */
			wakeup-mask {
				mask = <0xfe3fffff>,	<0x0>,		<0x0>,		<0x0>,
				       <0x0>,		<0x0>,		<0x0>,		<0x0>,
				       <0x0220ffef>,	<0x8007ff6f>,	<0x8007ff6f>,	<0x0>,
				       <0x8007ff6f>,	<0x8007ff6f>;
				mask-offset = <0x3944>;
				stat-offset = <0x3950>;
			};
			wakeup-mask2 {
				mask = <0x3e1e>,	<0x0>,		<0x0>,		<0x0>,
				       <0x0>,		<0x0>,		<0x0>,		<0x0>,
				       <0x0>,	<0x3e1e>,	<0x3e1e>,	<0x0>,
				       <0x3e1e>,	<0x3e1e>;
				mask-offset = <0x3964>;
				stat-offset = <0x3954>;
			};
		};
	};

	tmuctrl_0: LITTLE0@10070000 {
		compatible = "samsung,exynos3830-tmu";
		reg = <0x0 0x10070000 0x800>;
		interrupts = <0 INTREQ__TMU 0>;
		tmu_name = "LITTLE0";
		id = <0>;
		sensors = <2>;
		sensing_mode = "max";
		#include "exynos3830-tmu-sensor-conf.dtsi"
	};

	tmuctrl_1: LITTLE1@10070000 {
		compatible = "samsung,exynos3830-tmu";
		reg = <0x0 0x10070000 0x800>;
		interrupts = <0 INTREQ__TMU 0>;
		tmu_name = "LITTLE1";
		id = <1>;
		sensors = <4>;
		sensing_mode = "max";
		hotplug_enable = <1>;
		hotplug_in_threshold = <91>;
		hotplug_out_threshold = <96>;
		#include "exynos9630-tmu-sensor-conf.dtsi"
	};

	tmuctrl_2: G3D@10070000 {
		compatible = "samsung,exynos3830-tmu";
		reg = <0x0 0x10070000 0x800>;
		interrupts = <0 INTREQ__TMU 0>;
		tmu_name = "G3D";
		id = <2>;
		sensors = <8>;
		sensing_mode = "max";
		#include "exynos3830-tmu-sensor-conf.dtsi"
	};

	acpm_tmu {
		acpm-ipc-channel = <9>;
	};

	thermal-zones {
		lit0_thermal: LITTLE0 {
			zone_name = "LITTLE0_THERMAL";
			polling-delay-passive = <0>;
			polling-delay = <1000>;
			thermal-sensors = <&tmuctrl_0>;

			trips {
				lit0_alert0: lit0-alert0 {
					temperature = <20000>;
					hysteresis = <5000>; /* millicelsius */
					type = "active";
				};
				lit0_alert1: lit0-alert1 {
					temperature = <76000>; /* millicelsius */
					hysteresis = <2000>; /* millicelsius */
					type = "active";
				};
				lit0_alert2: lit0-alert2 {
					temperature = <81000>; /* millicelsius */
					hysteresis = <5000>; /* millicelsius */
					type = "active";
				};
				lit0_alert3: lit0-alert3 {
					temperature = <86000>; /* millicelsius */
					hysteresis = <5000>; /* millicelsius */
					type = "active";
				};
				lit0_alert4: lit0-alert4 {
					temperature = <91000>; /* millicelsius */
					hysteresis = <5000>; /* millicelsius */
					type = "active";
				};
				lit0_alert5: lit0-alert5 {
					temperature = <96000>; /* millicelsius */
					hysteresis = <5000>; /* millicelsius */
					type = "active";
				};
				lit0_alert6: lit0-alert6 {
					temperature = <101000>; /* millicelsius */
					hysteresis = <5000>; /* millicelsius */
					type = "active";
				};
				lit0_hot: lit0-hot {
					temperature = <115000>; /* millicelsius */
					hysteresis = <5000>; /* millicelsius */
					type = "hot";
				};
			};
			cooling-maps {
				map0 {
					trip = <&lit0_alert0>;
					cooling-device = <&cpufreq_domain0 0 0>;
				};
				map1 {
					trip = <&lit0_alert1>;
					cooling-device = <&cpufreq_domain0 0 0>;
				};
				map2 {
					trip = <&lit0_alert2>;
					cooling-device = <&cpufreq_domain0 0 0>;
				};
				map3 {
					trip = <&lit0_alert3>;
					cooling-device = <&cpufreq_domain0 0 0>;
				};
				map4 {
					trip = <&lit0_alert4>;
					cooling-device = <&cpufreq_domain0 0 0>;
				};
				map5 {
					trip = <&lit0_alert5>;
					cooling-device = <&cpufreq_domain0 0 0>;
				};
				map6 {
					trip = <&lit0_alert6>;
					cooling-device = <&cpufreq_domain0 0 0>;
				};
				map7 {
					trip = <&lit0_hot>;
					cooling-device = <&cpufreq_domain0 0 0>;
				};
			};
		};

		lit1_thermal: LITTLE1 {
			zone_name = "LITTLE1_THERMAL";
			polling-delay-passive = <0>;
			polling-delay = <0>;
			thermal-sensors = <&tmuctrl_1>;

			trips {
				lit1_alert0: lit1-alert0 {
					temperature = <20000>;
					hysteresis = <5000>; /* millicelsius */
					type = "active";
				};
				lit1_alert1: lit1-alert1 {
					temperature = <76000>; /* millicelsius */
					hysteresis = <2000>; /* millicelsius */
					type = "active";
				};
				lit1_alert2: lit1-alert2 {
					temperature = <81000>; /* millicelsius */
					hysteresis = <5000>; /* millicelsius */
					type = "active";
				};
				lit1_alert3: lit1-alert3 {
					temperature = <86000>; /* millicelsius */
					hysteresis = <5000>; /* millicelsius */
					type = "active";
				};
				lit1_alert4: lit1-alert4 {
					temperature = <91000>; /* millicelsius */
					hysteresis = <5000>; /* millicelsius */
					type = "active";
				};
				lit1_alert5: lit1-alert5 {
					temperature = <96000>; /* millicelsius */
					hysteresis = <5000>; /* millicelsius */
					type = "active";
				};
				lit1_alert6: lit1-alert6 {
					temperature = <101000>; /* millicelsius */
					hysteresis = <5000>; /* millicelsius */
					type = "active";
				};
				lit1_hot: lit1-hot {
					temperature = <115000>; /* millicelsius */
					hysteresis = <5000>; /* millicelsius */
					type = "hot";
				};
			};
			cooling-maps {
				map0 {
					trip = <&lit1_alert0>;
					cooling-device = <&cpufreq_domain1 0 0>;
				};
				map1 {
					trip = <&lit1_alert1>;
					cooling-device = <&cpufreq_domain1 0 0>;
				};
				map2 {
					trip = <&lit1_alert2>;
					cooling-device = <&cpufreq_domain1 0 0>;
				};
				map3 {
					trip = <&lit1_alert3>;
					cooling-device = <&cpufreq_domain1 0 0>;
				};
				map4 {
					trip = <&lit1_alert4>;
					cooling-device = <&cpufreq_domain1 0 0>;
				};
				map5 {
					trip = <&lit1_alert5>;
					cooling-device = <&cpufreq_domain1 0 0>;
				};
				map6 {
					trip = <&lit1_alert6>;
					cooling-device = <&cpufreq_domain1 0 0>;
				};
				map7 {
					trip = <&lit1_hot>;
					cooling-device = <&cpufreq_domain1 0 0>;
				};
			};
		};

		gpu_thermal: G3D {
			zone_name = "G3D_THERMAL";
			polling-delay-passive = <0>;
			polling-delay = <0>;
			thermal-sensors = <&tmuctrl_2>;

			trips {
				gpu_alert0: gpu-alert0 {
					temperature = <20000>;
					hysteresis = <5000>; /* millicelsius */
					type = "active";
				};
				gpu_alert1: gpu-alert1 {
					temperature = <76000>; /* millicelsius */
					hysteresis = <2000>; /* millicelsius */
					type = "active";
				};
				gpu_alert2: gpu-alert2 {
					temperature = <81000>; /* millicelsius */
					hysteresis = <5000>; /* millicelsius */
					type = "active";
				};
				gpu_alert3: gpu-alert3 {
					temperature = <86000>; /* millicelsius */
					hysteresis = <5000>; /* millicelsius */
					type = "active";
				};
				gpu_alert4: gpu-alert4 {
					temperature = <91000>; /* millicelsius */
					hysteresis = <5000>; /* millicelsius */
					type = "active";
				};
				gpu_alert5: gpu-alert5 {
					temperature = <96000>; /* millicelsius */
					hysteresis = <5000>; /* millicelsius */
					type = "active";
				};
				gpu_alert6: gpu-alert6 {
					temperature = <101000>; /* millicelsius */
					hysteresis = <5000>; /* millicelsius */
					type = "active";
				};
				gpu_hot: gpu-hot {
					temperature = <115000>; /* millicelsius */
					hysteresis = <5000>; /* millicelsius */
					type = "hot";
				};
			};
			cooling-maps {
				map0 {
					trip = <&gpu_alert0>;
					cooling-device = <&mali 0 0>;
				};
				map1 {
					trip = <&gpu_alert1>;
					cooling-device = <&mali 0 0>;
				};
				map2 {
					trip = <&gpu_alert2>;
					cooling-device = <&mali 0 0>;
				};
				map3 {
					trip = <&gpu_alert3>;
					cooling-device = <&mali 0 0>;
				};
				map4 {
					trip = <&gpu_alert4>;
					cooling-device = <&mali 0 0>;
				};
				map5 {
					trip = <&gpu_alert5>;
					cooling-device = <&mali 0 0>;
				};
				map6 {
					trip = <&gpu_alert6>;
					cooling-device = <&mali 0 0>;
				};
				map7 {
					trip = <&gpu_hot>;
					cooling-device = <&mali 0 0>;
				};
			};
		};
	};

	fm@14AC0000 {
		compatible = "samsung,exynos3830-fm";
		reg = <0x0 0x14AC0000 0x2000>,
			<0x0 0x14800800 0x10>;
		//elna_gpio = <&gpg2 3 0x1>; /* FM_LNA_EN */
		//pinctrl-names = "default";
		//pinctrl-0 = <&fm_lna_en>;
		clocks = <&clock UMUX_CLK_AUD_FM>,
			<&clock GATE_ABOX_QCH_FM>,
			<&clock DOUT_CLK_AUD_FM>;  /* mux_aud_fm, qch_fm, clk_aud_fm */
		clock-names = "mux_aud_fm", "qch_fm", "clk_aud_fm";
		samsung,syscon-phandle = <&pmu_system_controller>;
		samsung,power-domain = <&pd_aud>;
		//status = "okay";
		status = "disabled";
	};

	tzasc {
		compatible = "samsung,exynos-tzasc";
		channel = <2>;
		tzc_ver = <380>;
		irqcnt = <2>;
		interrupts = <GIC_SPI INTREQ__DMC_INTR_MIF0 IRQ_TYPE_LEVEL_HIGH>,
			     <GIC_SPI INTREQ__DMC_INTR_MIF1 IRQ_TYPE_LEVEL_HIGH>;
	};

	contexthub_0: contexthub {
		compatible = "samsung,exynos-nanohub";
		/* INTREQ_MAILBOX_CHUB2AP, INTREQ_WDT_CHUB */
		interrupts = <0 50 0>,<0 73 0>;
		clocks = <&clock DOUT_CLK_CHUB_BUS>;
		clock-names = "chub_bus";
		pinctrl-names = "spi_suspend","spi_resume","i2c_suspend","i2c_resume";
		pinctrl-0 = <&sensor_spi_suspend>;
		pinctrl-1 = <&sensor_spi_resume>;
		pinctrl-2 = <&sensor_i2c_suspend>;
		pinctrl-3 = <&sensor_i2c_resume>;
		/* mailbox, sram, dumpgpr, chub reset &
		chub cpu reset, baaw_p_apm_shub, chub cpu clock */
		reg =	<0x0 0x11a00000 0x200>,	/* MAILBOX_AP_CHUB */
			<0x0 0x10e00000 0x40000>, /* intMEM_Instr */
			<0x0 0x10cf0000 0x100>,	/* DUMP_GPR_SHUB */
			<0x0 0x11862d00 0x10>,	/* CHUB_CPU_CONFIGURATION */
			<0x0 0x10d20000 0x10>,	/* BAAW_C_SHUB to access the mailbox and rtc */
			<0x0 0x11800800 0x10>,	/*CHUB_CMU_CHUB_CONTROLLER_OPTION*/
			<0x0 0x11bd0040 0x10>;    /* GPH2_CON */
	        reg-names = "mailbox", "sram", "dumpgpr",
		                "chub_reset", "chub_baaw",
				"cmu_chub_qch", "vdd_sensor_en";
		/* BAAW_C_SHUB = BAAW_P_APM_CHUB */
		baaw,baaw-p-apm-chub = <0x40300 0x40900 0x11900>;
		/* none, pass, os.checked_0.bin */
		os-type = "os.checked_0.bin";
	};
};
